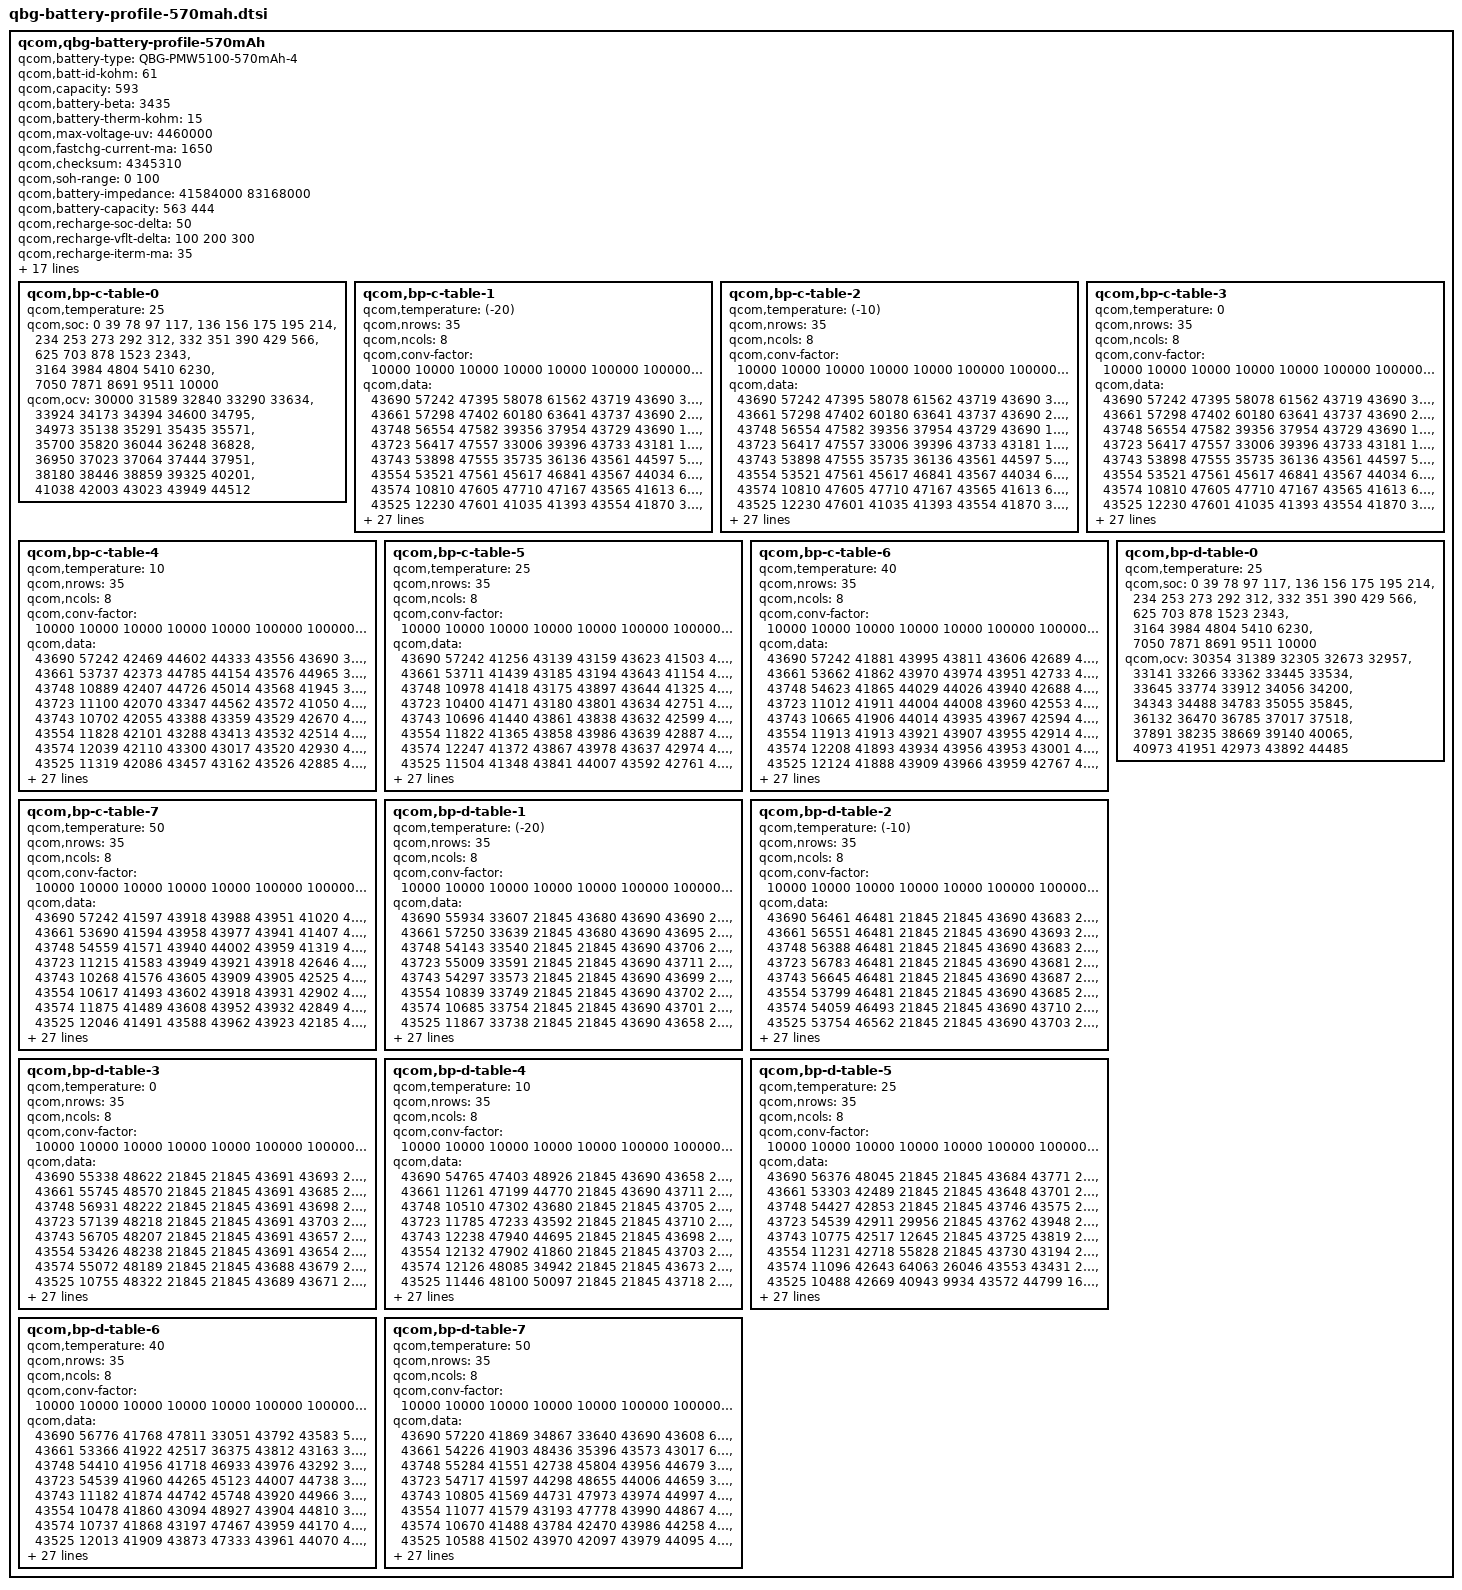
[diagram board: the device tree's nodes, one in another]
qcom,qbg-battery-profile-570mAh {
	qcom,battery-type = "QBG-PMW5100-570mAh-4";
	qcom,batt-id-kohm = <61>;
	qcom,capacity = <593>;
	qcom,battery-beta = <3435>;
	qcom,battery-therm-kohm = <15>;
	qcom,max-voltage-uv = <4460000>;
	qcom,fastchg-current-ma = <1650>;
	qcom,checksum = <4345310>; /*@5, 0.007V, 8% */
	qcom,soh-range = <0 100>;
	/* Nominal_Impedance in 10nohm @ SOC 50% 25C* 0:fresh cell,  1: aged cell */
	qcom,battery-impedance = <41584000 83168000>;
	/* Nominal_Capacity in mAh. 0: fresh cell,  1:aged cell */
	qcom,battery-capacity = <563 444>;
	/* SOC delta (in percent) dropped from EOC SOC to enable recharge */
	qcom,recharge-soc-delta =<50>;
	/* vfloat delta (in mV) dropped from regular vfloat in recharge */
	qcom,recharge-vflt-delta =<100 200 300>;
	/* Termination current (in mA) in recharge */
	qcom,recharge-iterm-ma = <35>;
	qcom,batt-temp-coeffs = <0 20 70 170 425 435 440  450 530>;
	qcom,batt-current-coeffs = <0 100000 250000 525000 1650000 700000 300000 300000 300000>;
	qcom,batt-max-mv-coeffs = <4130000 4460000>;
	qcom,chg-limit-current-default = <100000 200000>;

	qcom,jeita-fcc-ranges = <0 170 525000
				171 440 1650000
				441 530 300000>;

	 qcom,jeita-fv-ranges = <0 170 4460000
				171 440 4460000
				441 530 4130000>;

	qcom,step-chg-ranges = <3400000 4250000 1650000
				4250001 4350000 1275000
				4350001 4460000 650000>;

	/* COOL = 15 DegC, WARM = 70 DegC */
	qcom,jeita-soft-thresholds = <0x30DD 0x7BC>;
	/* COLD = 0 DegC, HOT = 80 DegC */
	qcom,jeita-hard-thresholds = <0x3733 0x5ed>;
	/* COOL = 18 DegC, WARM = 39 DegC*/
	qcom,jeita-soft-hys-thresholds = <0x256e 0x161b>;
	qcom,jeita-soft-fcc-ua = <100000 1650000>;
	qcom,jeita-soft-fv-uv = <4130000 4460000>;

	qcom,bp-c-table-0 {
		qcom,temperature = <25>;
		qcom,soc = <    0    39    78    97   117>,
			<  136   156   175   195   214>,
			<  234   253   273   292   312>,
			<  332   351   390   429   566>,
			<  625   703   878  1523  2343>,
			< 3164  3984  4804  5410  6230>,
			< 7050  7871  8691  9511 10000>;
		qcom,ocv = <30000 31589 32840 33290 33634>,
			<33924 34173 34394 34600 34795>,
			<34973 35138 35291 35435 35571>,
			<35700 35820 36044 36248 36828>,
			<36950 37023 37064 37444 37951>,
			<38180 38446 38859 39325 40201>,
			<41038 42003 43023 43949 44512>;
	};

	qcom,bp-c-table-1 {
		qcom,temperature = <(-20)>;
		qcom,nrows = <35>;
		qcom,ncols = <8>;
		qcom,conv-factor = <10000 10000 10000 10000 10000 100000 100000 10000>;
		qcom,data = <43690 57242 47395 58078 61562 43719 43690 32081>,
			<43661 57298 47402 60180 63641 43737 43690 27209>,
			<43748 56554 47582 39356 37954 43729 43690 12542>,
			<43723 56417 47557 33006 39396 43733 43181 11997>,
			<43743 53898 47555 35735 36136 43561 44597 50226>,
			<43554 53521 47561 45617 46841 43567 44034 61610>,
			<43574 10810 47605 47710 47167 43565 41613 60754>,
			<43525 12230 47601 41035 41393 43554 41870 37728>,
			<43625  9140 47602 44115 44061 43564 41742 39447>,
			<43644  8222 47612 45012 44874 43566 41786 34602>,
			<43584  8500 47615 44699 44872 43733 41611 33123>,
			<43607  9980 47609 43113 44882 43731 44901 32989>,
			<43963  9792 47609 43996 44217 43742 43516 33744>,
			<43918 10179 47608 43555 44175 43739 43998 33390>,
			<43922 10058 47608 43665 44213 43738 43638 33516>,
			<44006  9464 47613 43672 44205 43741 43633 36162>,
			<44021  9232 47562 43649 44866 43567 43632 36150>,
			<43820  9677 47582 43657 44807 43534 43632 36227>,
			<43783  9547 47568 43659 44839 43546 43633 35948>,
			<43164 14852 47565 43711 45019 43911 43594 36726>,
			<43227 14947 47591 43686 45014 43839 43594 36639>,
			<43029 14926 47517 43700 44856 43620 43603 36613>,
			<43460 15232 47585 43698 44809 43976 43946 36830>,
			<44889 14407 47533 44566 43498 43630 41040 36684>,
			<41869 15894 47224 44980 44604 43621 42733 36725>,
			<42742 16342 47156 45042 44612 43621 42588 36861>,
			<42298 15576 47313 44846 44650 43628 42656 36564>,
			<47214 15730 47295 44853 44845 43619 41746 36380>,
			<49032 13082 47987 45053 45046 43617 41441 35175>,
			<45820 14260 47971 44995 43232 43926 41728 35483>,
			<45344  2691 48000 44862 43074 43945 41961 35545>,
			<46101  2334 47716 44912 43326 43615 41477 35803>,
			<35673  3365 47865 44265 44849 43627 44119 36477>,
			<36749   403 47681 44908 42784 43630 44711 39163>,
			<36282  2040 47645 43649 42161 43562 43951 38984>;
	};

	qcom,bp-c-table-2 {
		qcom,temperature = <(-10)>;
		qcom,nrows = <35>;
		qcom,ncols = <8>;
		qcom,conv-factor = <10000 10000 10000 10000 10000 100000 100000 10000>;
		qcom,data = <43690 57242 47395 58078 61562 43719 43690 32081>,
			<43661 57298 47402 60180 63641 43737 43690 27209>,
			<43748 56554 47582 39356 37954 43729 43690 12542>,
			<43723 56417 47557 33006 39396 43733 43181 11997>,
			<43743 53898 47555 35735 36136 43561 44597 50226>,
			<43554 53521 47561 45617 46841 43567 44034 61610>,
			<43574 10810 47605 47710 47167 43565 41613 60754>,
			<43525 12230 47601 41035 41393 43554 41870 37728>,
			<43625  9140 47602 44115 44061 43564 41742 39447>,
			<43644  8222 47612 45012 44874 43566 41786 34602>,
			<43584  8500 47615 44699 44872 43733 41611 33123>,
			<43607  9980 47609 43113 44882 43731 44901 32989>,
			<43963  9792 47609 43996 44217 43742 43516 33744>,
			<43918 10179 47608 43555 44175 43739 43998 33390>,
			<43922 10058 47608 43665 44213 43738 43638 33516>,
			<44006  9464 47613 43672 44205 43741 43633 36162>,
			<44021  9232 47562 43649 44866 43567 43632 36150>,
			<43820  9677 47582 43657 44807 43534 43632 36227>,
			<43783  9547 47568 43659 44839 43546 43633 35948>,
			<43164 14852 47565 43711 45019 43911 43594 36726>,
			<43227 14947 47591 43686 45014 43839 43594 36639>,
			<43029 14926 47517 43700 44856 43620 43603 36613>,
			<43460 15232 47585 43698 44809 43976 43946 36830>,
			<44889 14407 47533 44566 43498 43630 41040 36684>,
			<41869 15894 47224 44980 44604 43621 42733 36725>,
			<42742 16342 47156 45042 44612 43621 42588 36861>,
			<42298 15576 47313 44846 44650 43628 42656 36564>,
			<47214 15730 47295 44853 44845 43619 41746 36380>,
			<49032 13082 47987 45053 45046 43617 41441 35175>,
			<45820 14260 47971 44995 43232 43926 41728 35483>,
			<45344  2691 48000 44862 43074 43945 41961 35545>,
			<46101  2334 47716 44912 43326 43615 41477 35803>,
			<35673  3365 47865 44265 44849 43627 44119 36477>,
			<36749   403 47681 44908 42784 43630 44711 39163>,
			<36282  2040 47645 43649 42161 43562 43951 38984>;
	};

	qcom,bp-c-table-3 {
		qcom,temperature = <0>;
		qcom,nrows = <35>;
		qcom,ncols = <8>;
		qcom,conv-factor = <10000 10000 10000 10000 10000 100000 100000 10000>;
		qcom,data = <43690 57242 47395 58078 61562 43719 43690 32081>,
			<43661 57298 47402 60180 63641 43737 43690 27209>,
			<43748 56554 47582 39356 37954 43729 43690 12542>,
			<43723 56417 47557 33006 39396 43733 43181 11997>,
			<43743 53898 47555 35735 36136 43561 44597 50226>,
			<43554 53521 47561 45617 46841 43567 44034 61610>,
			<43574 10810 47605 47710 47167 43565 41613 60754>,
			<43525 12230 47601 41035 41393 43554 41870 37728>,
			<43625  9140 47602 44115 44061 43564 41742 39447>,
			<43644  8222 47612 45012 44874 43566 41786 34602>,
			<43584  8500 47615 44699 44872 43733 41611 33123>,
			<43607  9980 47609 43113 44882 43731 44901 32989>,
			<43963  9792 47609 43996 44217 43742 43516 33744>,
			<43918 10179 47608 43555 44175 43739 43998 33390>,
			<43922 10058 47608 43665 44213 43738 43638 33516>,
			<44006  9464 47613 43672 44205 43741 43633 36162>,
			<44021  9232 47562 43649 44866 43567 43632 36150>,
			<43820  9677 47582 43657 44807 43534 43632 36227>,
			<43783  9547 47568 43659 44839 43546 43633 35948>,
			<43164 14852 47565 43711 45019 43911 43594 36726>,
			<43227 14947 47591 43686 45014 43839 43594 36639>,
			<43029 14926 47517 43700 44856 43620 43603 36613>,
			<43460 15232 47585 43698 44809 43976 43946 36830>,
			<44889 14407 47533 44566 43498 43630 41040 36684>,
			<41869 15894 47224 44980 44604 43621 42733 36725>,
			<42742 16342 47156 45042 44612 43621 42588 36861>,
			<42298 15576 47313 44846 44650 43628 42656 36564>,
			<47214 15730 47295 44853 44845 43619 41746 36380>,
			<49032 13082 47987 45053 45046 43617 41441 35175>,
			<45820 14260 47971 44995 43232 43926 41728 35483>,
			<45344  2691 48000 44862 43074 43945 41961 35545>,
			<46101  2334 47716 44912 43326 43615 41477 35803>,
			<35673  3365 47865 44265 44849 43627 44119 36477>,
			<36749   403 47681 44908 42784 43630 44711 39163>,
			<36282  2040 47645 43649 42161 43562 43951 38984>;
	};

	qcom,bp-c-table-4 {
		qcom,temperature = <10>;
		qcom,nrows = <35>;
		qcom,ncols = <8>;
		qcom,conv-factor = <10000 10000 10000 10000 10000 100000 100000 10000>;
		qcom,data = <43690 57242 42469 44602 44333 43556 43690 36664>,
			<43661 53737 42373 44785 44154 43576 44965 35277>,
			<43748 10889 42407 44726 45014 43568 41945 35772>,
			<43723 11100 42070 43347 44562 43572 41050 46424>,
			<43743 10702 42055 43388 43359 43529 42670 46193>,
			<43554 11828 42101 43288 43413 43532 42514 46963>,
			<43574 12039 42110 43300 43017 43520 42930 46680>,
			<43525 11319 42086 43457 43162 43526 42885 46725>,
			<43625 11730 42093 43491 43864 43527 42924 45373>,
			<43644  8937 42092 43406 43849 43527 42741 45452>,
			<43584  8790 42082 43090 43888 43546 41087 45166>,
			<43607  8972 42081 43105 43902 43544 41543 45275>,
			<43963  8424 42084 43020 43876 43551 44441 45190>,
			<43918  8318 42106 43066 43872 43538 44185 45917>,
			<43922  8692 42106 43047 43886 43539 44169 45925>,
			<44006  8565 42085 43047 43796 43536 44264 45829>,
			<44021  9970 42084 43044 43794 43542 44229 45881>,
			<43820 10140 42082 43067 43802 43626 44061 46031>,
			<43783  9384 42000 43047 43803 43630 44036 45974>,
			<43164 14981 42196 43208 43803 43620 44227 45595>,
			<43227 14906 42180 43211 43785 43621 44039 45783>,
			<43029 14955 42186 43053 43818 43642 41697 45819>,
			<43460 14939 42202 43018 43784 43647 41892 45795>,
			<44889 14379 42212 43406 43026 43599 41423 45656>,
			<41869 15919 42114 43469 43288 43584 42515 45982>,
			<42742 16359 42817 43311 43355 43587 42995 45692>,
			<42298 15592 42849 43282 43283 43595 42885 45823>,
			<47214 15738 42791 43383 43388 43639 41546 45749>,
			<49032 13265 42946 43292 45037 43592 41848 45635>,
			<45820 14259 42914 43509 43221 43637 41087 49149>,
			<45344  2794 42527 43307 43014 43639 41967 49151>,
			<46101  2397 42742 43278 43446 43637 44371 49023>,
			<35673  3419 42631 43343 43339 43595 44334 48514>,
			<36749   306 42640 44730 41669 43599 44652 46877>,
			<36282  1799 42744 43192 41548 43536 43175 46139>;
	};

	qcom,bp-c-table-5 {
		qcom,temperature = <25>;
		qcom,nrows = <35>;
		qcom,ncols = <8>;
		qcom,conv-factor = <10000 10000 10000 10000 10000 100000 100000 10000>;
		qcom,data = <43690 57242 41256 43139 43159 43623 41503 47548>,
			<43661 53711 41439 43185 43194 43643 41154 47141>,
			<43748 10978 41418 43175 43897 43644 41325 47276>,
			<43723 10400 41471 43180 43801 43634 42751 47977>,
			<43743 10696 41440 43861 43838 43632 42599 47918>,
			<43554 11822 41365 43858 43986 43639 42887 48099>,
			<43574 12247 41372 43867 43978 43637 42974 48063>,
			<43525 11504 41348 43841 44007 43592 42761 47682>,
			<43625 11650 41347 43855 44008 43598 42770 47721>,
			<43644 11585 41356 43850 43926 43596 42767 47628>,
			<43584  8759 41353 43888 43933 43587 42946 47655>,
			<43607  9192 41397 43902 43929 43590 42929 47837>,
			<43963  9073 41398 43877 43930 43588 42621 47822>,
			<43918  8385 41394 43878 43908 43610 42524 47870>,
			<43922  8281 41406 43878 43910 43608 42607 47853>,
			<44006  8670 41383 43878 43904 43614 42566 47766>,
			<44021  8518 41389 43879 43917 43615 42941 47769>,
			<43820  9830 41045 43878 43918 43603 42890 47797>,
			<43783 10034 41044 43883 43917 43604 42720 47789>,
			<43164  9590 41079 43815 43926 43936 41769 42258>,
			<43227 15100 41076 43823 43930 43939 41137 42277>,
			<43029 14901 41037 43823 43966 43951 42642 42442>,
			<43460 14946 41063 43835 44002 43938 41053 42452>,
			<44889 14574 40987 43796 43151 43943 41968 47748>,
			<41869 16021 41002 43871 43086 43937 41248 47644>,
			<42742 16270 41209 43172 43117 43938 42909 47858>,
			<42298 15492 41149 43165 43062 43946 41450 47790>,
			<47214 15713 41855 43252 43076 43601 44492 47751>,
			<49032 13111 41743 43164 43307 43939 44438 47845>,
			<45820 14243 41967 43850 43794 43602 41745 42781>,
			<45344  2788 41588 43892 43840 43615 44394 42795>,
			<46101  3769 41515 43183 43259 43604 44526 42772>,
			<35673   677 41698 43243 43103 43945 44416 42023>,
			<36749   263 41698 43219 44940 43962 44078 48091>,
			<36282  1866 41687 43819 44441 43959 43046 47545>;
	};

	qcom,bp-c-table-6 {
		qcom,temperature = <40>;
		qcom,nrows = <35>;
		qcom,ncols = <8>;
		qcom,conv-factor = <10000 10000 10000 10000 10000 100000 100000 10000>;
		qcom,data = <43690 57242 41881 43995 43811 43606 42689 42613>,
			<43661 53662 41862 43970 43974 43951 42733 42510>,
			<43748 54623 41865 44029 44026 43940 42688 42701>,
			<43723 11012 41911 44004 44008 43960 42553 42720>,
			<43743 10665 41906 44014 43935 43967 42594 42628>,
			<43554 11913 41913 43921 43907 43955 42914 42686>,
			<43574 12208 41893 43934 43956 43953 43001 41303>,
			<43525 12124 41888 43909 43966 43959 42767 41283>,
			<43625 11369 41901 43911 43942 43956 42836 41331>,
			<43644 11567 41902 43911 43951 43957 42182 41318>,
			<43584  8860 41898 43911 43605 43956 42079 41320>,
			<43607  8816 41559 43908 43600 43956 42287 41234>,
			<43963  9176 41552 43908 43615 43959 47778 41221>,
			<43918  8360 41565 43909 43611 43959 47809 41229>,
			<43922  8225 41566 43908 43590 43957 47617 41271>,
			<44006  8609 41562 43911 43597 43915 47729 41273>,
			<44021  8494 41543 43910 43593 43913 48045 41248>,
			<43820  9934 41538 43905 43639 43917 48094 41431>,
			<43783 10116 41548 43910 43632 43906 47167 41427>,
			<43164  9688 41585 43915 43617 43928 48123 41466>,
			<43227 15020 41596 43947 43627 44008 42031 41398>,
			<43029 15054 41593 43634 43537 44028 41335 41028>,
			<43460 14880 41575 43590 43586 44006 41820 41359>,
			<44889 15180 41493 43907 44001 44000 42517 41243>,
			<41869 14692 41486 43957 43874 44024 40986 42659>,
			<42742 15939 41684 43953 43992 43922 42719 41255>,
			<42298 15527 41726 43925 43822 43910 41963 41268>,
			<47214 15720 41608 43983 43871 43915 44043 42670>,
			<49032 13074 44376 44018 43845 43919 44486 41320>,
			<45820 14244 44290 43948 43603 44011 41000 41098>,
			<45344  2762 44519 43963 43922 43923 41491 41148>,
			<46101  3712 44112 43928 43837 43932 41677 41196>,
			<35673   692 44049 44023 43168 43926 41672 40967>,
			<36749   274 44039 43985 43400 43916 44092 41291>,
			<36282  1876 44072 43949 44716 44009 43095 42720>;
	};

	qcom,bp-c-table-7 {
		qcom,temperature = <50>;
		qcom,nrows = <35>;
		qcom,ncols = <8>;
		qcom,conv-factor = <10000 10000 10000 10000 10000 100000 100000 10000>;
		qcom,data = <43690 57242 41597 43918 43988 43951 41020 42669>,
			<43661 53690 41594 43958 43977 43941 41407 41339>,
			<43748 54559 41571 43940 44002 43959 41319 41270>,
			<43723 11215 41583 43949 43921 43918 42646 41257>,
			<43743 10268 41576 43605 43909 43905 42525 41409>,
			<43554 10617 41493 43602 43918 43931 42902 41471>,
			<43574 11875 41489 43608 43952 43932 42849 41451>,
			<43525 12046 41491 43588 43962 43923 42185 41349>,
			<43625 11482 41500 43590 43938 43921 42409 41354>,
			<43644 11675 41502 43590 43947 43926 42256 41401>,
			<43584 11592 41499 43585 43601 43921 47652 41379>,
			<43607  8751 41477 43585 43612 43921 48077 41045>,
			<43963  9143 41479 43584 43611 43921 47233 41052>,
			<43918  8966 41473 43584 43585 43921 47214 41031>,
			<43922  8350 41474 43584 43598 43921 47509 41033>,
			<44006  8223 41487 43587 43639 43926 47378 41075>,
			<44021  8580 41481 43586 43645 43926 48768 41061>,
			<43820  9892 41524 43597 43622 43927 48757 41066>,
			<43783  9842 41521 43597 43631 44011 49101 40991>,
			<43164  9661 41532 43596 43539 44026 45709 40970>,
			<43227  9488 41528 43645 43528 43982 48229 41179>,
			<43029 14989 41511 43548 43566 43988 47892 41092>,
			<43460 15076 41504 43536 43551 43984 41369 41161>,
			<44889 15115 41514 43639 43601 43972 42598 41064>,
			<41869 14626 41669 43640 44031 43821 41101 41044>,
			<42742 15995 41720 43629 43937 43994 41416 41016>,
			<42298 15521 41606 43593 43921 44023 41604 41067>,
			<47214 15715 44368 43917 43987 44007 44414 41405>,
			<49032 13158 44391 43965 44016 43969 41860 40983>,
			<45820 14262 44323 43624 43630 43968 41269 41947>,
			<45344  2783 44419 43618 43938 43973 41982 41921>,
			<46101  3735 44152 43613 44027 43972 41067 41767>,
			<35673   646 44064 43950 43776 43981 41906 41732>,
			<36749   274 44224 43909 43233 44020 41479 41160>,
			<36282  1193 44258 43640 43324 43971 43393 41454>;
	};

	qcom,bp-d-table-0 {
		qcom,temperature = <25>;
		qcom,soc = <    0    39    78    97   117>,
			<  136   156   175   195   214>,
			<  234   253   273   292   312>,
			<  332   351   390   429   566>,
			<  625   703   878  1523  2343>,
			< 3164  3984  4804  5410  6230>,
			< 7050  7871  8691  9511 10000>;
		qcom,ocv = <30354 31389 32305 32673 32957>,
			<33141 33266 33362 33445 33534>,
			<33645 33774 33912 34056 34200>,
			<34343 34488 34783 35055 35845>,
			<36132 36470 36785 37017 37518>,
			<37891 38235 38669 39140 40065>,
			<40973 41951 42973 43892 44485>;
	};

	qcom,bp-d-table-1 {
		qcom,temperature = <(-20)>;
		qcom,nrows = <35>;
		qcom,ncols = <8>;
		qcom,conv-factor = <10000 10000 10000 10000 10000 100000 100000 10000>;
		qcom,data = <43690 55934 33607 21845 43680 43690 43690 21845>,
			<43661 57250 33639 21845 43680 43690 43695 21845>,
			<43748 54143 33540 21845 21845 43690 43706 21845>,
			<43723 55009 33591 21845 21845 43690 43711 21845>,
			<43743 54297 33573 21845 21845 43690 43699 21845>,
			<43554 10839 33749 21845 21845 43690 43702 21845>,
			<43574 10685 33754 21845 21845 43690 43701 21845>,
			<43525 11867 33738 21845 21845 43690 43658 21845>,
			<43625 11344 33786 21845 21845 43690 43658 21845>,
			<43644  8432 33771 21845 21845 43690 43701 21845>,
			<43584  9420 33694 21845 21845 43690 43703 21845>,
			<43607 14479 33679 21845 21845 43690 43697 21845>,
			<43963 15880 33714 21845 21845 43690 43699 21845>,
			<43918 16265 33711 21845 21845 43690 43709 21845>,
			<43922 15873 33344 21845 21845 43690 43711 21845>,
			<44006 14599 33381 21845 21845 43690 43710 21845>,
			<44021 14379 33298 21845 21845 43690 43705 21845>,
			<43820 15272 33292 21845 21845 43690 43707 21845>,
			<43783 15272 33339 21845 21845 43690 43704 21845>,
			<43164 15307 33451 21845 21845 43690 43699 21845>,
			<43227 15269 36117 21845 21845 43688 43018 21845>,
			<43029  9569 36231 21845 41549 43683 41456 21845>,
			<43460 15055 35952 21845 48893 43681 44764 21845>,
			<44889 15330 36451  2632 47650 43692 43137 21845>,
			<41869 14350 35197 56518 41990 43688 43139 21845>,
			<42742 14691 36566 61904 42791 43688 43234 23436>,
			<42298 15968 35185 60782 42599 43688 43193 28835>,
			<47214 16199 35312 37406 42724 43688 43173 25279>,
			<49032 15800 35180 34062 42550 43688 43149  6083>,
			<45820 12436 36532 33237 48719 43689 44646  5342>,
			<45344 13464 35311 32907 35454 43689 44734 27898>,
			<46101  2885 35252 33621 36467 43689 43111 25207>,
			<35673  3243 34846 33988 35920 43689 43058 26057>,
			<36749   219 35671 40736 35249 43689 43866 32310>,
			<36282  1878 35772 38410 45191 43689 43819 30842>;
	};

	qcom,bp-d-table-2 {
		qcom,temperature = <(-10)>;
		qcom,nrows = <35>;
		qcom,ncols = <8>;
		qcom,conv-factor = <10000 10000 10000 10000 10000 100000 100000 10000>;
		qcom,data = <43690 56461 46481 21845 21845 43690 43683 21845>,
			<43661 56551 46481 21845 21845 43690 43693 21845>,
			<43748 56388 46481 21845 21845 43690 43683 21845>,
			<43723 56783 46481 21845 21845 43690 43681 21845>,
			<43743 56645 46481 21845 21845 43690 43687 21845>,
			<43554 53799 46481 21845 21845 43690 43685 21845>,
			<43574 54059 46493 21845 21845 43690 43710 21845>,
			<43525 53754 46562 21845 21845 43690 43703 21845>,
			<43625 55049 46536 21845 21845 43690 43650 21845>,
			<43644 10933 46556 21845 21845 43690 43674 21845>,
			<43584 10441 46557 21845 21845 43690 43679 21845>,
			<43607 11861 46567 21845 21845 43690 43678 21845>,
			<43963  9098 46173 21845 21845 43690 43675 21845>,
			<43918 10091 46117 21845 21845 43690 43649 21845>,
			<43922 15215 46209 21845 21845 43690 43660 21845>,
			<44006 16039 46920 21845 21845 43690 43656 21845>,
			<44021 16048 46953 21845 21845 43690 43658 21845>,
			<43820 14486 46852 21366 21845 43690 43702 21845>,
			<43783 15050 46858 27890 21845 43690 43696 21845>,
			<43164 15061 46636  1560 18456 43689 43252 21845>,
			<43227  9710 46801 21156 48997 43681 42807 21845>,
			<43029  9678 45395 30222 41544 43680 41800 21845>,
			<43460  9483 45395  1558 41353 43689 43011 21845>,
			<44889 15244 45506 64534 41032 43688 43018 26154>,
			<41869 14444 45320 34637 41139 43688 43124 14000>,
			<42742 14718 45480 45950 41548 43689 43022 10888>,
			<42298 15892 45086 42442 41638 43694 43208 51014>,
			<47214 15522 45081 41184 41513 43692 43055 52173>,
			<49032 15684 45183 42659 42668 43680 44623 51387>,
			<45820 12544 45113 42703 48986 43563 44874 49608>,
			<45344 13780 45311 42176 45112 43581 44577 56030>,
			<46101  2487 45927 47836 48586 43563 44751 55984>,
			<35673  3507 45919 48074 48495 43730 44766 56970>,
			<36749   122 45988 47159 49083 43682 43152 55614>,
			<36282  1878 45775 47417 47303 43690 43690 51091>;
	};

	qcom,bp-d-table-3 {
		qcom,temperature = <0>;
		qcom,nrows = <35>;
		qcom,ncols = <8>;
		qcom,conv-factor = <10000 10000 10000 10000 10000 100000 100000 10000>;
		qcom,data = <43690 55338 48622 21845 21845 43691 43693 21845>,
			<43661 55745 48570 21845 21845 43691 43685 21845>,
			<43748 56931 48222 21845 21845 43691 43698 21845>,
			<43723 57139 48218 21845 21845 43691 43703 21845>,
			<43743 56705 48207 21845 21845 43691 43657 21845>,
			<43554 53426 48238 21845 21845 43691 43654 21845>,
			<43574 55072 48189 21845 21845 43688 43679 21845>,
			<43525 10755 48322 21845 21845 43689 43671 21845>,
			<43625 10289 48362 21845 21845 43694 43755 21845>,
			<43644 10519 48264 16748 21845 43694 43669 21845>,
			<43584 11441 48296  7523 21845 43689 43666 21845>,
			<43607  9120 48970 12097 21845 43688 43653 21845>,
			<43963  8554 48918 62961 21845 43691 43660 21845>,
			<43918 10200 48947 59387 21845 43691 43658 21845>,
			<43922 10086 49116 65474 21845 43691 43732 21845>,
			<44006 10065 49145 50934 21845 43688 43162 21845>,
			<44021  9355 49029  9166 21845 43694 44607 21845>,
			<43820  9464 48717  7975 26653 43682 41670 21845>,
			<43783  9410 48703  4223 52533 43682 44289 21845>,
			<43164  9315 48806  9605 42033 43688 43106 23415>,
			<43227  9311 48811 49512 42929 43688 43043 31982>,
			<43029  9608 47450 58289 41387 43688 43068  6296>,
			<43460  9692 47459 33685 41513 43688 43012  9116>,
			<44889 15285 47558 42538 44460 43695 43098 62330>,
			<41869 14402 47557 44232 44045 43707 43347 59488>,
			<42742 14708 47598 43453 44816 43745 43280 40100>,
			<42298 15989 47589 43225 45052 43740 44937 34291>,
			<47214 15382 47523 44572 44217 43626 44419 33814>,
			<49032 12854 47178 45034 41710 43631 44105 34166>,
			<45820 14025 47155 44129 47819 43622 44835 37589>,
			<45344 13681 47315 44363 42811 43545 44709 40001>,
			<46101  2357 47288 41649 42669 43534 44980 39954>,
			<35673  3391 47901 44371 42581 43523 45044 37696>,
			<36749   409 48065 44531 41180 43534 44615 37100>,
			<36282  1880 47655 44148 44289 43574 44974 40247>;
	};

	qcom,bp-d-table-4 {
		qcom,temperature = <10>;
		qcom,nrows = <35>;
		qcom,ncols = <8>;
		qcom,conv-factor = <10000 10000 10000 10000 10000 100000 100000 10000>;
		qcom,data = <43690 54765 47403 48926 21845 43690 43658 21845>,
			<43661 11261 47199 44770 21845 43690 43711 21845>,
			<43748 10510 47302 43680 21845 21845 43705 21845>,
			<43723 11785 47233 43592 21845 21845 43710 21845>,
			<43743 12238 47940 44695 21845 21845 43698 21845>,
			<43554 12132 47902 41860 21845 21845 43703 21845>,
			<43574 12126 48085 34942 21845 21845 43673 21845>,
			<43525 11446 48100 50097 21845 21845 43718 21845>,
			<43625 11501 48008 26652 21845 21845 43548 21845>,
			<43644 11473 47696 21845 21845 19718 43957 21845>,
			<43584 11286 47737 21845 21845 41825 43776 21845>,
			<43607 11711 47616 21845 15727 43707 43141 21845>,
			<43963 11572 47827 21845 63692 43707 43018 21845>,
			<43918  8855 47843 21845 34073 43706 43124 21845>,
			<43922  8820 47755 32735 36657 43684 43087 21845>,
			<44006  9176 47785  3562 46558 43686 43083 21724>,
			<44021  9029 42330  8676 45438 43682 43132 17400>,
			<43820  8305 42363 62864 48197 43689 43106 24616>,
			<43783  8476 42242 59708 47368 43688 43086  1978>,
			<43164  9401 42458 49122 42128 43694 43361 52379>,
			<43227  9229 42457 47854 42617 43692 43328 62264>,
			<43029  9658 42302 41261 41124 43680 43286 57644>,
			<43460  9505 42488 44048 44034 43703 44691 37698>,
			<44889 14919 42488 43313 44754 43717 44884 36305>,
			<41869 14455 42415 43091 43350 43536 44297 46414>,
			<42742 14711 42096 43013 43414 43634 44540 46725>,
			<42298 16271 42087 43077 43372 43592 41626 45560>,
			<47214 15438 42195 43447 43366 43592 41646 45251>,
			<49032 12820 42230 43504 45003 43646 44530 45326>,
			<45820 13857 42209 44749 41262 43595 44655 34878>,
			<45344 13636 42824 44552 44464 43625 44793 46135>,
			<46101  2326 42858 44586 44170 43541 45006 46212>,
			<35673  3356 42757 44747 44153 43624 44888 46416>,
			<36749   485 42882 44733 44251 43643 44222 35718>,
			<36282  1865 42532 43289 44592 43620 44621 35445>;
	};

	qcom,bp-d-table-5 {
		qcom,temperature = <25>;
		qcom,nrows = <35>;
		qcom,ncols = <8>;
		qcom,conv-factor = <10000 10000 10000 10000 10000 100000 100000 10000>;
		qcom,data = <43690 56376 48045 21845 21845 43684 43771 21845>,
			<43661 53303 42489 21845 21845 43648 43701 21845>,
			<43748 54427 42853 21845 21845 43746 43575 21845>,
			<43723 54539 42911 29956 21845 43762 43948 21845>,
			<43743 10775 42517 12645 21845 43725 43819 21845>,
			<43554 11231 42718 55828 21845 43730 43194 21845>,
			<43574 11096 42643 64063 26046 43553 43431 21845>,
			<43525 10488 42669 40943  9934 43572 44799 16841>,
			<43625 10255 41332 35462 63011 43547 44861 12629>,
			<43644 10324 41320 47104 37922 43541 44074 49407>,
			<43584 10695 41246 42954 39625 43619 44135 65219>,
			<43607 10564 41223 41068 36167 43641 44104 58010>,
			<43963 11986 41228 41581 35800 43639 44123 37961>,
			<43918 12194 41227 44516 46629 43596 44113 40256>,
			<43922 12082 41268 44271 45685 43590 44462 38917>,
			<44006 11405 41270 44862 48299 43591 44455 33801>,
			<44021 11282 41267 44984 47389 43586 44466 33229>,
			<43820 11637 41253 44786 47850 43634 44442 35885>,
			<43783  8773 41259 43387 42961 43622 44522 34825>,
			<43164  9903 41366 43030 44463 43542 44526 45865>,
			<43227 10126 41344 43065 44889 43551 44493 48498>,
			<43029  9436 41361 43040 44804 43628 44439 48521>,
			<43460  9499 41354 43157 44549 43609 44152 49049>,
			<44889 14899 41073 43814 43146 43608 44146 47690>,
			<41869 14372 40983 43986 43866 43936 41708 42328>,
			<42742 16041 40996 43786 43491 43966 44326 47731>,
			<42298 16369 41211 43792 43119 43949 44387 42326>,
			<47214 15783 41100 43782 43159 43946 44322 42430>,
			<49032 12878 41810 43846 43412 43615 44402 47759>,
			<45820 13867 41832 43217 44915 43613 44562 47512>,
			<45344  2727 41946 43247 43299 43636 44796 47817>,
			<46101  2421 41904 43163 43016 43644 44850 42374>,
			<35673  3447 41543 43144 43066 43636 44048 42408>,
			<36749   478 41537 43857 43084 43610 44097 42454>,
			<36282  1903 41860 43903 43420 43600 44808 42311>;
	};

	qcom,bp-d-table-6 {
		qcom,temperature = <40>;
		qcom,nrows = <35>;
		qcom,ncols = <8>;
		qcom,conv-factor = <10000 10000 10000 10000 10000 100000 100000 10000>;
		qcom,data = <43690 56776 41768 47811 33051 43792 43583 57887>,
			<43661 53366 41922 42517 36375 43812 43163 38795>,
			<43748 54410 41956 41718 46933 43976 43292 39934>,
			<43723 54539 41960 44265 45123 44007 44738 33096>,
			<43743 11182 41874 44742 45748 43920 44966 36268>,
			<43554 10478 41860 43094 48927 43904 44810 34896>,
			<43574 10737 41868 43197 47467 43959 44170 46425>,
			<43525 12013 41909 43873 47333 43961 44070 46240>,
			<43625 12223 41904 43791 48016 43936 44123 46621>,
			<43644 12135 41919 43810 47869 43944 44519 45339>,
			<43584 11481 41915 43993 42281 43601 44342 45165>,
			<43607 11686 41895 43977 42034 43613 44402 45933>,
			<43963 11574 41891 44018 42951 43615 41642 45608>,
			<43918  8885 41902 44005 41294 43612 41654 48206>,
			<43922  8765 41898 44002 41091 43602 41625 49077>,
			<44006  9123 41558 44008 41683 43600 41709 47554>,
			<44021  9171 41554 43927 44475 43607 41712 47954>,
			<43820  8432 41563 43929 45005 43945 41685 47763>,
			<43783  8606 41537 43907 44777 43940 41483 42410>,
			<43164 10091 41591 43906 43047 43956 41847 42887>,
			<43227  9218 41587 43910 43240 43919 41882 42613>,
			<43029  9675 41593 43930 43856 43916 41664 42559>,
			<43460  9546 41575 43956 43999 43923 41604 41304>,
			<44889 14959 41497 43945 43907 44007 41404 41416>,
			<41869 14374 41533 43641 44030 44030 44359 41374>,
			<42742 16029 41690 43602 43066 44023 44493 42715>,
			<42298 16338 41698 43591 43807 44001 44437 41457>,
			<47214 15755 41653 43608 43981 44009 41866 41049>,
			<49032 12884 41640 43904 43228 44015 41700 42626>,
			<45820 13864 44411 43994 43413 43916 44670 42890>,
			<45344 13694 44348 43926 43872 43958 45013 41351>,
			<46101  2353 44526 44015 43926 43964 41733 41163>,
			<35673  3387 44471 43917 43904 43911 41817 41798>,
			<36749   400 44102 43950 43993 43909 41519 41799>,
			<36282  1798 44104 43947 43882 43594 41649 41185>;
	};

	qcom,bp-d-table-7 {
		qcom,temperature = <50>;
		qcom,nrows = <35>;
		qcom,ncols = <8>;
		qcom,conv-factor = <10000 10000 10000 10000 10000 100000 100000 10000>;
		qcom,data = <43690 57220 41869 34867 33640 43690 43608 62358>,
			<43661 54226 41903 48436 35396 43573 43017 61079>,
			<43748 55284 41551 42738 45804 43956 44679 34206>,
			<43723 54717 41597 44298 48655 44006 44659 36047>,
			<43743 10805 41569 44731 47973 43974 44997 46345>,
			<43554 11077 41579 43193 47778 43990 44867 45322>,
			<43574 10670 41488 43784 42470 43986 44258 45308>,
			<43525 10588 41502 43970 42097 43979 44095 45832>,
			<43625 11879 41477 43926 42019 44010 44157 45961>,
			<43644 12070 41472 43956 42135 43915 44473 45592>,
			<43584 11408 41484 43936 42870 43943 44517 45699>,
			<43607 11378 41483 43605 42897 43937 44345 48625>,
			<43963 11725 41526 43613 42653 43942 44360 48277>,
			<43918 11584 41533 43610 41053 43940 41627 48721>,
			<43922  8910 41528 43585 41731 43941 41692 47386>,
			<44006  8816 41509 43597 41680 43963 41481 47145>,
			<44021  9188 41510 43593 44331 43961 41498 47912>,
			<43820  8322 41516 43633 44841 43958 41478 42436>,
			<43783  8286 41512 43647 43335 43916 41487 42860>,
			<43164 10193 41687 43641 43139 43921 41756 41306>,
			<43227  9461 41686 43632 43852 43922 41117 41216>,
			<43029  9605 41692 43591 43849 43923 41815 41233>,
			<43460  9498 41690 43603 43904 44000 42630 41385>,
			<44889 14883 41714 43640 43609 43971 42067 40992>,
			<41869 14582 41710 43525 43954 43834 41970 41153>,
			<42742 16030 41654 43541 43861 43786 44525 41442>,
			<42298 16171 41640 43543 44016 43809 41661 41006>,
			<47214 15745 44360 43547 43957 43818 41970 41141>,
			<49032 13225 44397 43639 43873 43992 41698 41035>,
			<45820 13870 44348 43911 43261 44010 44189 41219>,
			<45344 13668 44532 43946 44003 44010 44499 41102>,
			<46101  2362 44454 43590 43588 44013 41019 41926>,
			<35673  3370 44137 43647 43638 44016 42633 41538>,
			<36749   397 44253 43542 43943 43992 41801 41476>,
			<36282  1842 44279 43551 43925 44019 44913 41592>;
	};

};
